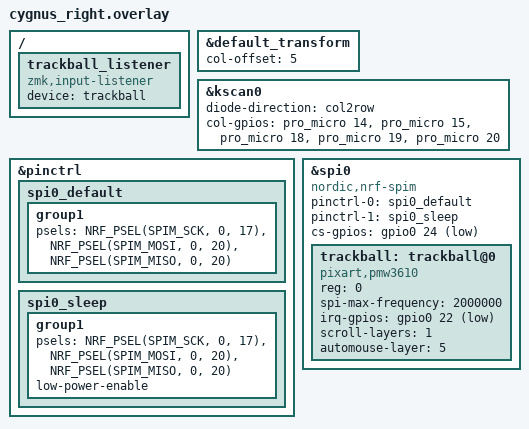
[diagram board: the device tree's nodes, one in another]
/*
 * Copyright (c) 2022 Duccio Breschi
 *
 * SPDX-License-Identifier: MIT
 */

#include "cygnus.dtsi"

&default_transform {
    col-offset = <5>;
};

&kscan0 {
    diode-direction = "col2row";
    col-gpios
        = <&pro_micro 14 GPIO_ACTIVE_HIGH>
        , <&pro_micro 15 GPIO_ACTIVE_HIGH>
        , <&pro_micro 18 GPIO_ACTIVE_HIGH>
        , <&pro_micro 19 GPIO_ACTIVE_HIGH>
        , <&pro_micro 20 GPIO_ACTIVE_HIGH>
    ;
};

&pinctrl {
    spi0_default: spi0_default {
        group1 {
            psels = <NRF_PSEL(SPIM_SCK, 0, 17)>,
                <NRF_PSEL(SPIM_MOSI, 0, 20)>,
                <NRF_PSEL(SPIM_MISO, 0, 20)>;
        };
    };

    spi0_sleep: spi0_sleep {
        group1 {
            psels = <NRF_PSEL(SPIM_SCK, 0, 17)>,
                <NRF_PSEL(SPIM_MOSI, 0, 20)>,
                <NRF_PSEL(SPIM_MISO, 0, 20)>;
            low-power-enable;
        };
    };
};

&spi0 {
    status = "okay";
    compatible = "nordic,nrf-spim";
    pinctrl-0 = <&spi0_default>;
    pinctrl-1 = <&spi0_sleep>;
    pinctrl-names = "default", "sleep";
    cs-gpios = <&gpio0 24 GPIO_ACTIVE_LOW>;

    trackball: trackball@0 {
        status = "okay";
        compatible = "pixart,pmw3610";
        reg = <0>;
        spi-max-frequency = <2000000>;
        irq-gpios = <&gpio0 22 (GPIO_ACTIVE_LOW | GPIO_PULL_UP)>;
        scroll-layers = <1>;  //切入1层则轨迹球进入滚轮模式
        // snipe-layers = <2>; //切入2层则轨迹球进入精准模式，意义不大，我屏蔽了
        automouse-layer = <5>; //在0层动球，自动切入5层，如果不需要，在前面加//
    };
};

/ {
    trackball_listener {
        compatible = "zmk,input-listener";
        device = <&trackball>;
    };
};
